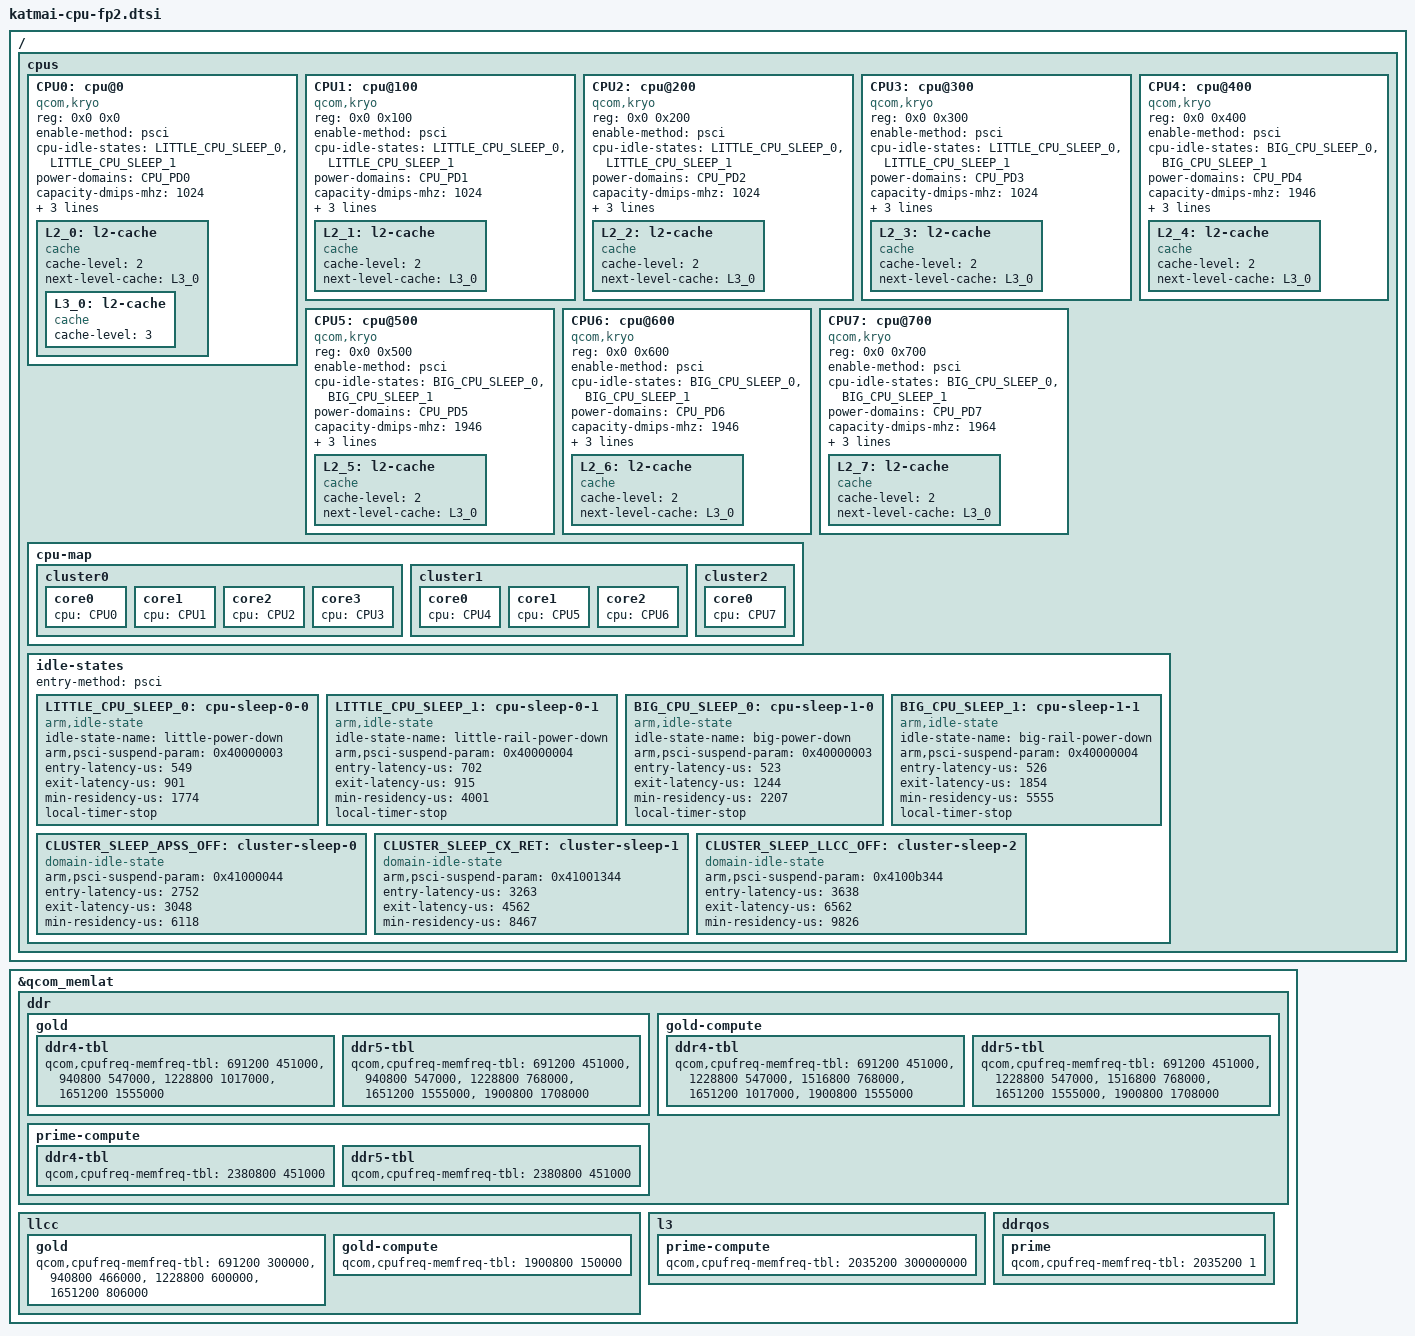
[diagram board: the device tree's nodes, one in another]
// SPDX-License-Identifier: BSD-3-Clause
/*
 * Copyright (c) 2025 Qualcomm Innovation Center, Inc. All rights reserved.
 */

/ {
	/delete-node/ cpus;
//	/delete-node/ energy-costs;

	cpus {
		#address-cells = <2>;
		#size-cells = <0>;

		CPU0: cpu@0 {
			device_type = "cpu";
			compatible = "qcom,kryo";
			reg = <0x0 0x0>;
			enable-method = "psci";
			cpu-idle-states = <&LITTLE_CPU_SLEEP_0 &LITTLE_CPU_SLEEP_1>;
			power-domains = <&CPU_PD0>;
			power-domain-names = "psci";
			capacity-dmips-mhz = <1024>;
			dynamic-power-coefficient = <100>;
			qcom,freq-domain = <&cpufreq_hw 0 4>;
			next-level-cache = <&L2_0>;
			#cooling-cells = <2>;
			L2_0: l2-cache {
			      compatible = "cache";
			      cache-level = <2>;
			      next-level-cache = <&L3_0>;

				L3_0: l2-cache {
				      compatible = "cache";
				      cache-level = <3>;
				};
			};
		};

		CPU1: cpu@100 {
			device_type = "cpu";
			compatible = "qcom,kryo";
			reg = <0x0 0x100>;
			enable-method = "psci";
			cpu-idle-states = <&LITTLE_CPU_SLEEP_0 &LITTLE_CPU_SLEEP_1>;
			power-domains = <&CPU_PD1>;
			power-domain-names = "psci";
			capacity-dmips-mhz = <1024>;
			dynamic-power-coefficient = <100>;
			qcom,freq-domain = <&cpufreq_hw 0 4>;
			next-level-cache = <&L2_1>;
			#cooling-cells = <2>;
			L2_1: l2-cache {
			      compatible = "cache";
			      cache-level = <2>;
			      next-level-cache = <&L3_0>;
			};
		};

		CPU2: cpu@200 {
			device_type = "cpu";
			compatible = "qcom,kryo";
			reg = <0x0 0x200>;
			enable-method = "psci";
			cpu-idle-states = <&LITTLE_CPU_SLEEP_0 &LITTLE_CPU_SLEEP_1>;
			power-domains = <&CPU_PD2>;
			power-domain-names = "psci";
			capacity-dmips-mhz = <1024>;
			dynamic-power-coefficient = <100>;
			qcom,freq-domain = <&cpufreq_hw 0 4>;
			next-level-cache = <&L2_2>;
			#cooling-cells = <2>;
			L2_2: l2-cache {
			      compatible = "cache";
			      cache-level = <2>;
			      next-level-cache = <&L3_0>;
			};
		};

		CPU3: cpu@300 {
			device_type = "cpu";
			compatible = "qcom,kryo";
			reg = <0x0 0x300>;
			enable-method = "psci";
			cpu-idle-states = <&LITTLE_CPU_SLEEP_0 &LITTLE_CPU_SLEEP_1>;
			power-domains = <&CPU_PD3>;
			power-domain-names = "psci";
			capacity-dmips-mhz = <1024>;
			dynamic-power-coefficient = <100>;
			qcom,freq-domain = <&cpufreq_hw 0 4>;
			next-level-cache = <&L2_3>;
			#cooling-cells = <2>;
			L2_3: l2-cache {
			      compatible = "cache";
			      cache-level = <2>;
			      next-level-cache = <&L3_0>;
			};
		};

		CPU4: cpu@400 {
			device_type = "cpu";
			compatible = "qcom,kryo";
			reg = <0x0 0x400>;
			enable-method = "psci";
			cpu-idle-states = <&BIG_CPU_SLEEP_0 &BIG_CPU_SLEEP_1>;
			power-domains = <&CPU_PD4>;
			power-domain-names = "psci";
			capacity-dmips-mhz = <1946>;
			dynamic-power-coefficient = <520>;
			qcom,freq-domain = <&cpufreq_hw 1 4>;
			next-level-cache = <&L2_4>;
			#cooling-cells = <2>;
			L2_4: l2-cache {
			      compatible = "cache";
			      cache-level = <2>;
			      next-level-cache = <&L3_0>;
			};
		};

		CPU5: cpu@500 {
			device_type = "cpu";
			compatible = "qcom,kryo";
			reg = <0x0 0x500>;
			enable-method = "psci";
			cpu-idle-states = <&BIG_CPU_SLEEP_0 &BIG_CPU_SLEEP_1>;
			power-domains = <&CPU_PD5>;
			power-domain-names = "psci";
			capacity-dmips-mhz = <1946>;
			dynamic-power-coefficient = <520>;
			qcom,freq-domain = <&cpufreq_hw 1 4>;
			next-level-cache = <&L2_5>;
			#cooling-cells = <2>;
			L2_5: l2-cache {
			      compatible = "cache";
			      cache-level = <2>;
			      next-level-cache = <&L3_0>;
			};
		};

		CPU6: cpu@600 {
			device_type = "cpu";
			compatible = "qcom,kryo";
			reg = <0x0 0x600>;
			enable-method = "psci";
			cpu-idle-states = <&BIG_CPU_SLEEP_0 &BIG_CPU_SLEEP_1>;
			power-domains = <&CPU_PD6>;
			power-domain-names = "psci";
			capacity-dmips-mhz = <1946>;
			dynamic-power-coefficient = <520>;
			qcom,freq-domain = <&cpufreq_hw 1 4>;
			next-level-cache = <&L2_6>;
			#cooling-cells = <2>;
			L2_6: l2-cache {
			      compatible = "cache";
			      cache-level = <2>;
			      next-level-cache = <&L3_0>;
			};
		};

		CPU7: cpu@700 {
			device_type = "cpu";
			compatible = "qcom,kryo";
			reg = <0x0 0x700>;
			enable-method = "psci";
			cpu-idle-states = <&BIG_CPU_SLEEP_0 &BIG_CPU_SLEEP_1>;
			power-domains = <&CPU_PD7>;
			power-domain-names = "psci";
			capacity-dmips-mhz = <1964>;
			dynamic-power-coefficient = <520>;
			qcom,freq-domain = <&cpufreq_hw 2 4>;
			next-level-cache = <&L2_7>;
			#cooling-cells = <2>;
			L2_7: l2-cache {
			      compatible = "cache";
			      cache-level = <2>;
			      next-level-cache = <&L3_0>;
			};
		};

		cpu-map {
			cluster0 {
				core0 {
					cpu = <&CPU0>;
				};

				core1 {
					cpu = <&CPU1>;
				};

				core2 {
					cpu = <&CPU2>;
				};

				core3 {
					cpu = <&CPU3>;
				};
			};

			cluster1 {
				core0 {
					cpu = <&CPU4>;
				};

				core1 {
					cpu = <&CPU5>;
				};

				core2 {
					cpu = <&CPU6>;
				};
			};

			cluster2 {
				core0 {
					cpu = <&CPU7>;
				};
			};
		};

		idle-states {
			entry-method = "psci";

			LITTLE_CPU_SLEEP_0: cpu-sleep-0-0 {
				compatible = "arm,idle-state";
				idle-state-name = "little-power-down";
				arm,psci-suspend-param = <0x40000003>;
				entry-latency-us = <549>;
				exit-latency-us = <901>;
				min-residency-us = <1774>;
				local-timer-stop;
			};

			LITTLE_CPU_SLEEP_1: cpu-sleep-0-1 {
				compatible = "arm,idle-state";
				idle-state-name = "little-rail-power-down";
				arm,psci-suspend-param = <0x40000004>;
				entry-latency-us = <702>;
				exit-latency-us = <915>;
				min-residency-us = <4001>;
				local-timer-stop;
			};

			BIG_CPU_SLEEP_0: cpu-sleep-1-0 {
				compatible = "arm,idle-state";
				idle-state-name = "big-power-down";
				arm,psci-suspend-param = <0x40000003>;
				entry-latency-us = <523>;
				exit-latency-us = <1244>;
				min-residency-us = <2207>;
				local-timer-stop;
			};

			BIG_CPU_SLEEP_1: cpu-sleep-1-1 {
				compatible = "arm,idle-state";
				idle-state-name = "big-rail-power-down";
				arm,psci-suspend-param = <0x40000004>;
				entry-latency-us = <526>;
				exit-latency-us = <1854>;
				min-residency-us = <5555>;
				local-timer-stop;
			};

			CLUSTER_SLEEP_APSS_OFF: cluster-sleep-0 {
				compatible = "domain-idle-state";
				arm,psci-suspend-param = <0x41000044>;
				entry-latency-us = <2752>;
				exit-latency-us = <3048>;
				min-residency-us = <6118>;
			};

			CLUSTER_SLEEP_CX_RET: cluster-sleep-1 {
				compatible = "domain-idle-state";
				arm,psci-suspend-param = <0x41001344>;
				entry-latency-us = <3263>;
				exit-latency-us = <4562>;
				min-residency-us = <8467>;
			};

			CLUSTER_SLEEP_LLCC_OFF: cluster-sleep-2 {
				compatible = "domain-idle-state";
				arm,psci-suspend-param = <0x4100b344>;
				entry-latency-us = <3638>;
				exit-latency-us = <6562>;
				min-residency-us = <9826>;
			};
		};
	};
};

&qcom_memlat {
	ddr {
		gold {
			ddr4-tbl {
				qcom,cpufreq-memfreq-tbl =
					<  691200  451000 >,
					<  940800  547000 >,
					< 1228800 1017000 >,
					< 1651200 1555000 >;
			};

			ddr5-tbl {
				qcom,cpufreq-memfreq-tbl =
					<  691200  451000 >,
					<  940800  547000 >,
					< 1228800  768000 >,
					< 1651200 1555000 >,
					< 1900800 1708000 >;
			};
		};

		gold-compute {
			ddr4-tbl {
				qcom,cpufreq-memfreq-tbl =
					<  691200  451000 >,
					< 1228800  547000 >,
					< 1516800  768000 >,
					< 1651200 1017000 >,
					< 1900800 1555000 >;
			};

			ddr5-tbl {
				qcom,cpufreq-memfreq-tbl =
					<  691200  451000 >,
					< 1228800  547000 >,
					< 1516800  768000 >,
					< 1651200 1555000 >,
					< 1900800 1708000 >;
			};
		};

		prime-compute {
			ddr4-tbl {
				qcom,cpufreq-memfreq-tbl =
					< 2380800  451000 >;
			};

			ddr5-tbl {
				qcom,cpufreq-memfreq-tbl =
					< 2380800  451000 >;
			};
		};
	};

	llcc {
		gold {
			qcom,cpufreq-memfreq-tbl =
				<  691200 300000 >,
				<  940800 466000 >,
				< 1228800 600000 >,
				< 1651200 806000 >;
		};

		gold-compute {
			qcom,cpufreq-memfreq-tbl =
				< 1900800  150000 >;
		};
	};

	l3 {
		prime-compute {
			qcom,cpufreq-memfreq-tbl =
				 < 2035200  300000000 >;
		 };
	};

	ddrqos {
		prime {
			qcom,cpufreq-memfreq-tbl =
				< 2035200 1 >;
		};
	};
};
